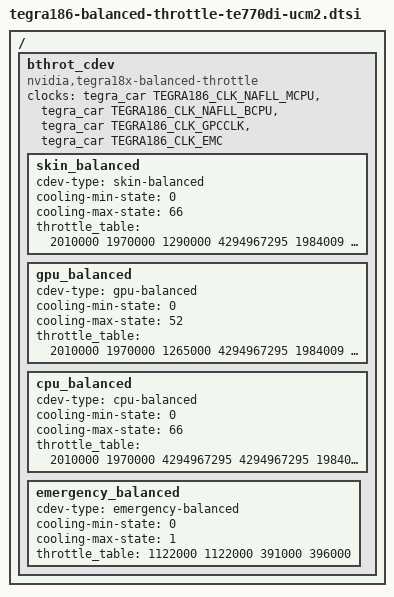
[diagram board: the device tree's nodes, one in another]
/*
 * arch/arm64/boot/dts/tegra186-platforms/tegra186-balanced-throttle-te770di-ucm2.dtsi
 *
 * Copyright (c) 2015-2016, NVIDIA CORPORATION.  All rights reserved.
 *
 * This program is free software; you can redistribute it and/or modify
 * it under the terms of the GNU General Public License as published by
 * the Free Software Foundation; version 2 of the License.
 *
 * This program is distributed in the hope that it will be useful, but WITHOUT
 * ANY WARRANTY; without even the implied warranty of MERCHANTABILITY or
 * FITNESS FOR A PARTICULAR PURPOSE.  See the GNU General Public License for
 * more details.
 *
 * You should have received a copy of the GNU General Public License along
 * with this program; if not, write to the Free Software Foundation, Inc.,
 * 51 Franklin Street, Fifth Floor, Boston, MA  02110-1301, USA.
 *
 */

/{
	bthrot_cdev {
		compatible = "nvidia,tegra18x-balanced-throttle";
		clocks = <&tegra_car TEGRA186_CLK_NAFLL_MCPU>,
				 <&tegra_car TEGRA186_CLK_NAFLL_BCPU>,
				 <&tegra_car TEGRA186_CLK_GPCCLK>,
				 <&tegra_car TEGRA186_CLK_EMC>;
		clock-names = "mcpu", "bcpu", "gpu", "emc";

		skin_balanced {
			cdev-type = "skin-balanced";
			cooling-min-state = <0>;
			cooling-max-state = <66>;
			#cooling-cells = <2>;
			throttle_table = <
				2010000	1970000	1290000	4294967295
				1984009	1944625	1273454	4294967295
				1958018	1919249	1256908	4294967295
				1932028	1893874	1240362	4294967295
				1906037	1868498	1223815	4294967295
				1880046	1843123	1207269	4294967295
				1854055	1817748	1190723	4294967295
				1828065	1792372	1174177	4294967295
				1802074	1766997	1157631	4294967295
				1776083	1741622	1141085	4294967295
				1750092	1716246	1124538	4294967295
				1724102	1690871	1107992	4294967295
				1698111	1665495	1091446	4294967295
				1672120	1640120	1074900	4294967295
				1646129	1614745	1058354	4294967295
				1620138	1589369	1041808	4294967295
				1594148	1563994	1025262	4294967295
				1568157	1538618	1008715	4294967295
				1542166	1513243	992169	4294967295
				1516175	1487868	975623	4294967295
				1490185	1462492	959077	4294967295
				1464194	1437117	942531	4294967295
				1438203	1411742	925985	4294967295
				1412212	1386366	909438	4294967295
				1386222	1360991	892892	4294967295
				1360231	1335615	876346	4294967295
				1334240	1310240	859800	4294967295
				1308249	1284865	843254	4294967295
				1282258	1259489	826708	4294967295
				1256268	1234114	810162	4294967295
				1230277	1208738	793615	4294967295
				1204286	1183363	777069	4294967295
				1178295	1157988	760523	4294967295
				1152305	1132612	743977	4294967295
				1126314	1107237	727431	4294967295
				1100323	1081862	710885	4294967295
				1074332	1056486	694338	4294967295
				1048342	1031111	677792	4294967295
				1022351	1005735	661246	4294967295
				996360	980360	644700	4294967295
				970369	954985	628154	4294967295
				944378	929609	611608	4294967295
				918388	904234	595062	4294967295
				892397	878858	578515	4294967295
				866406	853483	561969	4294967295
				840415	828108	545423	4294967295
				814425	802732	528877	4294967295
				788434	777357	512331	4294967295
				762443	751982	495785	4294967295
				736452	726606	479238	4294967295
				710462	701231	462692	4294967295
				684471	675855	446146	4294967295
				658480	650480	429600	4294967295
				632489	625105	413054	4294967295
				606498	599729	396508	4294967295
				580508	574354	379962	4294967295
				554517	548978	363415	4294967295
				528526	523603	346869	4294967295
				502535	498228	330323	4294967295
				476545	472852	313777	4294967295
				450554	447477	297231	4294967295
				424563	422102	280685	4294967295
				398572	396726	264138	4294967295
				372582	371351	247592	4294967295
				346591	345975	231046	4294967295
				320600	320600	214500	4294967295
			>;
		};
		gpu_balanced {
			cdev-type = "gpu-balanced";
			cooling-min-state = <0>;
			cooling-max-state = <52>;
			#cooling-cells = <2>;
			throttle_table = <
				2010000	1970000	1265000	4294967295
				1984009	1944625	1244402	4294967295
				1958018	1919249	1223804	4294967295
				1932028	1893874	1203206	4294967295
				1906037	1868498	1182608	4294967295
				1880046	1843123	1162010	4294967295
				1854055	1817748	1141412	4294967295
				1828065	1792372	1120814	4294967295
				1802074	1766997	1100216	4294967295
				1776083	1741622	1079618	4294967295
				1750092	1716246	1059020	4294967295
				1724102	1690871	1038422	4294967295
				1698111	1665495	1017824	4294967295
				1672120	1640120	997225	4294967295
				1646129	1614745	976627	4294967295
				1620138	1589369	956029	4294967295
				1594148	1563994	935431	4294967295
				1568157	1538618	914833	4294967295
				1542166	1513243	894235	4294967295
				1516175	1487868	873637	4294967295
				1490185	1462492	853039	4294967295
				1464194	1437117	832441	4294967295
				1438203	1411742	811843	4294967295
				1412212	1386366	791245	4294967295
				1386222	1360991	770647	4294967295
				1360231	1335615	750049	4294967295
				1334240	1310240	729451	4294967295
				1308249	1284865	708853	4294967295
				1282258	1259489	688255	4294967295
				1256268	1234114	667657	4294967295
				1230277	1208738	647059	4294967295
				1204286	1183363	626461	4294967295
				1178295	1157988	605863	4294967295
				1152305	1132612	585265	4294967295
				1126314	1107237	564667	4294967295
				1100323	1081862	544069	4294967295
				1074332	1056486	523471	4294967295
				1048342	1031111	502873	4294967295
				1022351	1005735	482275	4294967295
				996360	980360	461676	4294967295
				970369	954985	441078	4294967295
				944378	929609	420480	4294967295
				918388	904234	399882	4294967295
				892397	878858	379284	4294967295
				866406	853483	358686	4294967295
				840415	828108	338088	4294967295
				814425	802732	317490	4294967295
				788434	777357	296892	4294967295
				762443	751982	276294	4294967295
				736452	726606	255696	4294967295
				710462	701231	235098	4294967295
				684471	675855	214500	4294967295
			>;
		};
		cpu_balanced {
			cdev-type = "cpu-balanced";
			cooling-min-state = <0>;
			cooling-max-state = <66>;
			#cooling-cells = <2>;
			throttle_table = <
				2010000	1970000	4294967295	4294967295
				1984009	1944625	4294967295	4294967295
				1958018	1919249	4294967295	4294967295
				1932028	1893874	4294967295	4294967295
				1906037	1868498	4294967295	4294967295
				1880046	1843123	4294967295	4294967295
				1854055	1817748	4294967295	4294967295
				1828065	1792372	4294967295	4294967295
				1802074	1766997	4294967295	4294967295
				1776083	1741622	4294967295	4294967295
				1750092	1716246	1340000	4294967295
				1724102	1690871	1319536	4294967295
				1698111	1665495	1299073	4294967295
				1672120	1640120	1278609	4294967295
				1646129	1614745	1258145	4294967295
				1620138	1589369	1237682	4294967295
				1594148	1563994	1217218	4294967295
				1568157	1538618	1196755	4294967295
				1542166	1513243	1176291	4294967295
				1516175	1487868	1155827	4294967295
				1490185	1462492	1135364	4294967295
				1464194	1437117	1114900	4294967295
				1438203	1411742	1094436	4294967295
				1412212	1386366	1073973	4294967295
				1386222	1360991	1053509	4294967295
				1360231	1335615	1033045	4294967295
				1334240	1310240	1012582	4294967295
				1308249	1284865	992118	4294967295
				1282258	1259489	971655	4294967295
				1256268	1234114	951191	4294967295
				1230277	1208738	930727	4294967295
				1204286	1183363	910264	4294967295
				1178295	1157988	889800	4294967295
				1152305	1132612	869336	4294967295
				1126314	1107237	848873	4294967295
				1100323	1081862	828409	4294967295
				1074332	1056486	807945	4294967295
				1048342	1031111	787482	4294967295
				1022351	1005735	767018	4294967295
				996360	980360	746555	4294967295
				970369	954985	726091	4294967295
				944378	929609	705627	4294967295
				918388	904234	685164	4294967295
				892397	878858	664700	4294967295
				866406	853483	644236	4294967295
				840415	828108	623773	4294967295
				814425	802732	603309	4294967295
				788434	777357	582845	4294967295
				762443	751982	562382	4294967295
				736452	726606	541918	4294967295
				710462	701231	521455	4294967295
				684471	675855	500991	4294967295
				658480	650480	480527	4294967295
				632489	625105	460064	4294967295
				606498	599729	439600	4294967295
				580508	574354	419136	4294967295
				554517	548978	398673	4294967295
				528526	523603	378209	4294967295
				502535	498228	357745	4294967295
				476545	472852	337282	4294967295
				450554	447477	316818	4294967295
				424563	422102	296355	4294967295
				398572	396726	275891	4294967295
				372582	371351	255427	4294967295
				346591	345975	234964	4294967295
				320600	320600	214500	4294967295
			>;
		};
		emergency_balanced {
			cdev-type = "emergency-balanced";
			cooling-min-state = <0>;
			cooling-max-state = <1>;
			#cooling-cells = <2>;
			throttle_table = <
				1122000	1122000	391000	396000
			>;
		};
	};
};
